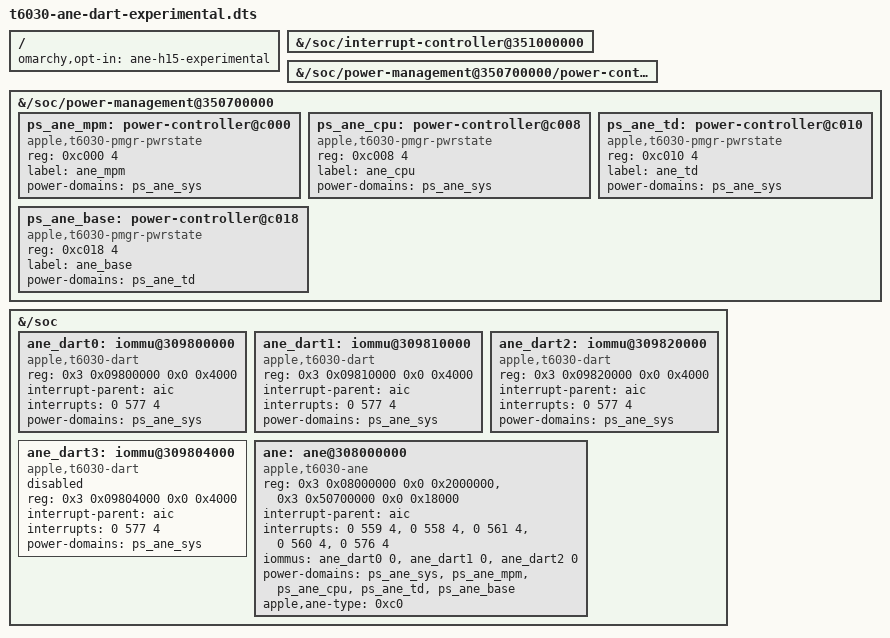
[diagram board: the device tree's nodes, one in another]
// SPDX-License-Identifier: GPL-2.0-only OR MIT
/*
 * ane/h15 OPT-IN EXPERIMENTAL overlay for T6030 (M3 Pro) board device
 * trees, DART variant: the same overlay as t6030-ane-experimental.dts with the three ANE DART
 * translation instances ENABLED (windows 0, 1 and 2: DARTLLT, DARTBRD, DARTBWR in the same-boot ADT of a J516S) and the
 * ane node a client of all three (iommus, stream 0 on each). Only for ane_h15 stage=5 map_fw=1,
 * and only after stage 4 found window 0 reading as a DART. The window at 0x309804000 is the DAPF aperture
 * (bank 0 + 0x4000), not a DART: it stays disabled. The ane node lists power-domains and so does
 * the DART nodes, so the kernel powers the ANE before the DART driver first touches it. An enabled
 * DART node without that hung a T6030 at boot (PR 173). Both the one-instance version of this file and this
 * three-instance file booted on a J516S without a hang. Each gave stage 5 `core-not-stopped` with no mailbox
 * message and no DART fault line (issue 176; the three-instance run showed three live streams after the attach).
 * If the machine hangs before display: power-cycle and boot without
 * the overlay. Stream 0 is the one stream the ADT names for the ANE (/arm-io/dart-ane sid = 0 and 15, bypass-15; the ane
 * node's iommu-parent is mapper-ane, reg 0); every working ANE overlay in this repo lists all its instances. All
 * three DART nodes use the one interrupt of the ADT (577), which the DART driver shares. Sources: the ADT facts are from the
 * same-boot ADT of a J516S (sha256 5cb4145e7c40bcb69ece333ce912c7956980e44977f7a369ab7ac459c3e79c0d, posted on issue 176 with
 * h15-adt-nodes.py output); the shared interrupt is requested with IRQF_SHARED at drivers/iommu/apple-dart.c:3115 of that
 * tester's kernel (source 77648eb7716845a7207ed6cdeadeea17b42c7a22, checked by the tester), where MAX_DARTS_PER_DEVICE is 8
 * and apple_dart_of_xlate records distinct providers; the one-instance result is on issue 176 (module f65f676826209fc0fe8e5b9d09b7879280faee31). Mirrors
 * ane/h15/t8122-ane-experimental.dts; the engine and
 * pmgr bases are MEASURED (ADT 27.0): engine 0x308000000+0x2000000,
 * pmgr 0x350700000+0x18000. The ps word set is the same five words,
 * the ANE_SYS word at +0x498 (parent LW20), the others at
 * +0xc000..+0xc018. IRQ lines and DART reg are per the ADT order.
 */
/dts-v1/;
/plugin/;

/ {
	omarchy,opt-in = "ane-h15-experimental";

	fragment@0 {
		target-path = "/soc/interrupt-controller@351000000";
		aic: __overlay__ {
		};
	};

	fragment@1 {
		target-path = "/soc/power-management@350700000/power-controller@498";
		ps_ane_sys: __overlay__ {
		};
	};

	fragment@2 {
		target-path = "/soc/power-management@350700000";
		__overlay__ {
			ps_ane_mpm: power-controller@c000 {
				compatible = "apple,t6030-pmgr-pwrstate", "apple,t8103-pmgr-pwrstate";
				reg = <0xc000 4>;
				#power-domain-cells = <0>;
				#reset-cells = <0>;
				label = "ane_mpm";
				power-domains = <&ps_ane_sys>;
			};
			ps_ane_cpu: power-controller@c008 {
				compatible = "apple,t6030-pmgr-pwrstate", "apple,t8103-pmgr-pwrstate";
				reg = <0xc008 4>;
				#power-domain-cells = <0>;
				#reset-cells = <0>;
				label = "ane_cpu";
				power-domains = <&ps_ane_sys>;
			};
			ps_ane_td: power-controller@c010 {
				compatible = "apple,t6030-pmgr-pwrstate", "apple,t8103-pmgr-pwrstate";
				reg = <0xc010 4>;
				#power-domain-cells = <0>;
				#reset-cells = <0>;
				label = "ane_td";
				power-domains = <&ps_ane_sys>;
			};
			ps_ane_base: power-controller@c018 {
				compatible = "apple,t6030-pmgr-pwrstate", "apple,t8103-pmgr-pwrstate";
				reg = <0xc018 4>;
				#power-domain-cells = <0>;
				#reset-cells = <0>;
				label = "ane_base";
				power-domains = <&ps_ane_td>;
			};
		};
	};

	fragment@3 {
		target-path = "/soc";

		__overlay__ {
			/* Instances 0, 1 and 2 of the ANE DART are enabled, the aperture window (instance 3) stays disabled. The DART driver probes an enabled node
			 * at boot, reading DART registers (the node has no apple,static-topology). On a T6030, equivalent enabled nodes
			 * hung the machine before display or network, because the ANE hardware behind them was not powered. This node
			 * lists power-domains to prevent that. That was not measured with this exact overlay: keep a way to boot without it. */
			ane_dart0: iommu@309800000 {
				compatible = "apple,t6030-dart", "apple,t8110-dart";
				reg = <0x3 0x09800000 0x0 0x4000>;
				#iommu-cells = <1>;
				interrupt-parent = <&aic>;
				interrupts = <0 577 4>;
				power-domains = <&ps_ane_sys>;
				status = "okay";
			};
			ane_dart1: iommu@309810000 {
				compatible = "apple,t6030-dart", "apple,t8110-dart";
				reg = <0x3 0x09810000 0x0 0x4000>;
				#iommu-cells = <1>;
				interrupt-parent = <&aic>;
				interrupts = <0 577 4>;
				power-domains = <&ps_ane_sys>;
				status = "okay";
			};
			ane_dart2: iommu@309820000 {
				compatible = "apple,t6030-dart", "apple,t8110-dart";
				reg = <0x3 0x09820000 0x0 0x4000>;
				#iommu-cells = <1>;
				interrupt-parent = <&aic>;
				interrupts = <0 577 4>;
				power-domains = <&ps_ane_sys>;
				status = "okay";
			};
			ane_dart3: iommu@309804000 {
				compatible = "apple,t6030-dart", "apple,t8110-dart";
				reg = <0x3 0x09804000 0x0 0x4000>;
				#iommu-cells = <1>;
				interrupt-parent = <&aic>;
				interrupts = <0 577 4>;
				power-domains = <&ps_ane_sys>;
				status = "disabled";
			};

			ane: ane@308000000 {
				compatible = "apple,t6030-ane";
				reg-names = "engine", "pmgr";
				reg = <0x3 0x08000000 0x0 0x2000000>,
				      <0x3 0x50700000 0x0 0x18000>;
				interrupt-parent = <&aic>;
				interrupts = <0 559 4>, <0 558 4>, <0 561 4>, <0 560 4>, <0 576 4>;
				/* Every enabled instance, stream 0: omarchy-ane-dt refuses a node that names a disabled provider. */
				iommus = <&ane_dart0 0>, <&ane_dart1 0>, <&ane_dart2 0>;
				power-domains = <&ps_ane_sys>, <&ps_ane_mpm>,
						<&ps_ane_cpu>, <&ps_ane_td>,
						<&ps_ane_base>;
				apple,ane-type = <0xc0>;
				status = "okay";
			};
		};
	};
};
